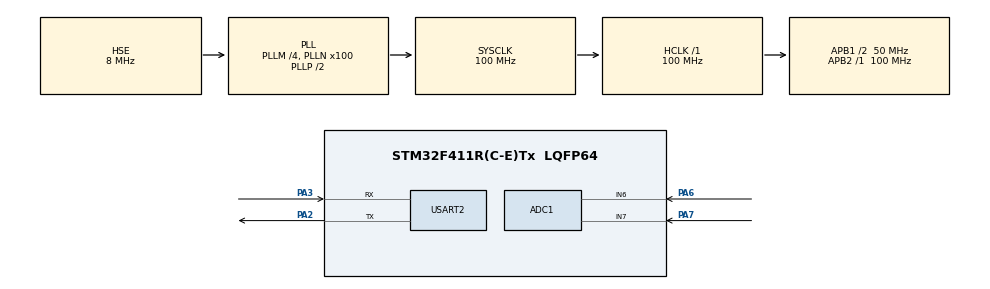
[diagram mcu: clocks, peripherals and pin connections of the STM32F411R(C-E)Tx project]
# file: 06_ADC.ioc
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ADC1.Channel-0\#ChannelRegularConversion=ADC_CHANNEL_7
ADC1.Channel-1\#ChannelRegularConversion=ADC_CHANNEL_6
ADC1.ContinuousConvMode=ENABLE
ADC1.DMAContinuousRequests=ENABLE
ADC1.InjNumberOfConversion=0
ADC1.NbrOfConversion=2
ADC1.NbrOfConversionFlag=1
ADC1.Rank-0\#ChannelRegularConversion=1
ADC1.Rank-1\#ChannelRegularConversion=2
ADC1.SamplingTime-0\#ChannelRegularConversion=ADC_SAMPLETIME_144CYCLES
ADC1.SamplingTime-1\#ChannelRegularConversion=ADC_SAMPLETIME_144CYCLES
ADC1.ScanConvMode=ENABLE
ADC1.master=1
Dma.ADC1.0.Direction=DMA_PERIPH_TO_MEMORY
Dma.ADC1.0.FIFOMode=DMA_FIFOMODE_DISABLE
Dma.ADC1.0.Instance=DMA2_Stream0
Dma.ADC1.0.MemDataAlignment=DMA_MDATAALIGN_HALFWORD
Dma.ADC1.0.MemInc=DMA_MINC_ENABLE
Dma.ADC1.0.Mode=DMA_CIRCULAR
Dma.ADC1.0.PeriphDataAlignment=DMA_PDATAALIGN_HALFWORD
Dma.ADC1.0.PeriphInc=DMA_PINC_DISABLE
Dma.ADC1.0.Priority=DMA_PRIORITY_LOW
Dma.Request0=ADC1
Mcu.Family=STM32F4
Mcu.Name=STM32F411R(C-E)Tx
Mcu.Package=LQFP64
NVIC.ADC_IRQn=true\:0\:0\:false\:false\:true\:true\:true\:true
NVIC.DMA2_Stream0_IRQn=true\:0\:0\:false\:false\:true\:false\:true\:true
NVIC.PriorityGroup=NVIC_PRIORITYGROUP_4
NVIC.USART2_IRQn=true\:0\:0\:false\:false\:true\:true\:true\:true
PA13.Mode=Serial_Wire
PA13.Signal=SYS_JTMS-SWDIO
PA14.Mode=Serial_Wire
PA14.Signal=SYS_JTCK-SWCLK
PA2.Mode=Asynchronous
PA2.Signal=USART2_TX
PA3.Mode=Asynchronous
PA3.Signal=USART2_RX
PA6.Signal=ADCx_IN6
PA7.Signal=ADCx_IN7
PH0\ -\ OSC_IN.Mode=HSE-External-Clock-Source
PH0\ -\ OSC_IN.Signal=RCC_OSC_IN
PH1\ -\ OSC_OUT.Mode=HSE-External-Clock-Source
PH1\ -\ OSC_OUT.Signal=RCC_OSC_OUT
ProjectManager.HeapSize=0x200
ProjectManager.StackSize=0x400
ProjectManager.TargetToolchain=STM32CubeIDE
RCC.48MHZClocksFreq_Value=50000000
RCC.AHBFreq_Value=100000000
RCC.APB1CLKDivider=RCC_HCLK_DIV2
RCC.APB1Freq_Value=50000000
RCC.APB1TimFreq_Value=100000000
RCC.APB2Freq_Value=100000000
RCC.APB2TimFreq_Value=100000000
RCC.CortexFreq_Value=100000000
RCC.HCLKFreq_Value=100000000
RCC.HSE_VALUE=8000000
RCC.HSI_VALUE=16000000
RCC.LSE_VALUE=32768
RCC.PLLM=4
RCC.PLLN=100
RCC.PLLSourceVirtual=RCC_PLLSOURCE_HSE
RCC.SYSCLKFreq_VALUE=100000000
RCC.SYSCLKSource=RCC_SYSCLKSOURCE_PLLCLK
RCC.VCOOutputFreq_Value=200000000
SH.ADCx_IN6.0=ADC1_IN6,IN6
SH.ADCx_IN7.0=ADC1_IN7,IN7
USART2.VirtualMode=VM_ASYNC
board=custom

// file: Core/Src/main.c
/* USER CODE BEGIN Header */
/**
  ******************************************************************************
  * @file           : main.c
  * @brief          : Main program body
  ******************************************************************************
  * @attention
  *
  * Copyright (c) 2026 STMicroelectronics.
  * All rights reserved.
  *
  * This software is licensed under terms that can be found in the LICENSE file
  * in the root directory of this software component.
  * If no LICENSE file comes with this software, it is provided AS-IS.
  *
  ******************************************************************************
  */
/* USER CODE END Header */
#include "main.h"
#include "adc.h"
#include "dma.h"
#include "usart.h"
#include "gpio.h"

/* USER CODE BEGIN Includes */
#include "stdio.h"
/* USER CODE END Includes */

/* USER CODE BEGIN PM */
#ifdef __GNUC__
  /* With GCC, small printf (option LD Linker->Libraries->Small printf
     set to 'Yes') calls __io_putchar() */
  #define PUTCHAR_PROTOTYPE int __io_putchar(int ch)
#else
  #define PUTCHAR_PROTOTYPE int fputc(int ch, FILE *f)
#endif /* __GNUC__ */
PUTCHAR_PROTOTYPE
{
  /* Place your implementation of __io_putchar() here */
  /* e.g. write a character to the usart2 and Loop until the end of transmission */
   HAL_UART_Transmit(&huart2, (uint8_t *)&ch, 1, 0xFFFF);

  return ch;
}
/* USER CODE END PM */

/* USER CODE BEGIN PV */
volatile uint16_t        adcValue[2];
//float       adcVoltage;

/* USER CODE END PV */

void SystemClock_Config(void);
/* USER CODE BEGIN PFP */

/* for interupt
void HAL_ADC_ConvCpltCallback(ADC_HandleTypeDef *hadc){
    adcValue = HAL_ADC_GetValue(&hadc1);

}
*/

/* USER CODE END PFP */

int main(void)
{

  /* MCU Configuration--------------------------------------------------------*/

  /* Reset of all peripherals, Initializes the Flash interface and the Systick. */
  HAL_Init();

  /* Configure the system clock */
  SystemClock_Config();

  /* Initialize all configured peripherals */
  MX_GPIO_Init();
  MX_DMA_Init();
  MX_USART2_UART_Init();
  MX_ADC1_Init();
  /* USER CODE BEGIN 2 */
  HAL_ADC_Start_DMA(&hadc1, (uint32_t * )adcValue, 2);
 // HAL_ADC_Start_IT(&hadc1); // interupt

  /* USER CODE END 2 */

  /* Infinite loop */
  /* USER CODE BEGIN WHILE */
  while (1)
  {
      printf("adc -> value1 : %4d\r\n",adcValue[0]);
      printf("adc -> value2 : %4d\r\n",adcValue[1]);

          HAL_Delay(300);

//      HAL_ADC_Start(&hadc1);
//      HAL_ADC_PollForConversion(&hadc1, 500);
//      adcValue = HAL_ADC_GetValue(&hadc1);
//      adcVoltage = 3.3 * ((float)adcValue/4095);
//      printf("adcValue = % d \r\ n",adcValue);
//      printf("adcVoltage = %f \r\n", adcVoltage);
//      HAL_Delay(500);

    /* USER CODE END WHILE */

  }
}

void SystemClock_Config(void)
{
  RCC_OscInitTypeDef RCC_OscInitStruct = {0};
  RCC_ClkInitTypeDef RCC_ClkInitStruct = {0};

  /** Configure the main internal regulator output voltage
  */
  __HAL_RCC_PWR_CLK_ENABLE();
  __HAL_PWR_VOLTAGESCALING_CONFIG(PWR_REGULATOR_VOLTAGE_SCALE1);

  /** Initializes the RCC Oscillators according to the specified parameters
  * in the RCC_OscInitTypeDef structure.
  */
  RCC_OscInitStruct.OscillatorType = RCC_OSCILLATORTYPE_HSE;
  RCC_OscInitStruct.HSEState = RCC_HSE_BYPASS;
  RCC_OscInitStruct.PLL.PLLState = RCC_PLL_ON;
  RCC_OscInitStruct.PLL.PLLSource = RCC_PLLSOURCE_HSE;
  RCC_OscInitStruct.PLL.PLLM = 4;
  RCC_OscInitStruct.PLL.PLLN = 100;
  RCC_OscInitStruct.PLL.PLLP = RCC_PLLP_DIV2;
  RCC_OscInitStruct.PLL.PLLQ = 4;
  if (HAL_RCC_OscConfig(&RCC_OscInitStruct) != HAL_OK)
  {
    Error_Handler();
  }

  /** Initializes the CPU, AHB and APB buses clocks
  */
  RCC_ClkInitStruct.ClockType = RCC_CLOCKTYPE_HCLK|RCC_CLOCKTYPE_SYSCLK
                              |RCC_CLOCKTYPE_PCLK1|RCC_CLOCKTYPE_PCLK2;
  RCC_ClkInitStruct.SYSCLKSource = RCC_SYSCLKSOURCE_PLLCLK;
  RCC_ClkInitStruct.AHBCLKDivider = RCC_SYSCLK_DIV1;
  RCC_ClkInitStruct.APB1CLKDivider = RCC_HCLK_DIV2;
  RCC_ClkInitStruct.APB2CLKDivider = RCC_HCLK_DIV1;

  if (HAL_RCC_ClockConfig(&RCC_ClkInitStruct, FLASH_LATENCY_3) != HAL_OK)
  {
    Error_Handler();
  }
}

void Error_Handler(void)
{
  __disable_irq();
  while (1)
  {
  }
}
